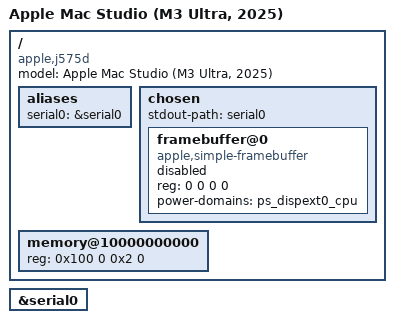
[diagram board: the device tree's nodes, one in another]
// SPDX-License-Identifier: GPL-2.0+ OR MIT
/*
 * Apple Mac Studio (M3 Ultra, 2025)
 *
 * target-type: J575d
 *
 * Copyright The Asahi Linux Contributors
 */

/dts-v1/;

#include "t6032.dtsi"

/ {
	compatible = "apple,j575d", "apple,t6032", "apple,arm-platform";
	model = "Apple Mac Studio (M3 Ultra, 2025)";

	aliases {
		serial0 = &serial0;
	};

	chosen {
		ranges;
		#address-cells = <2>;
		#size-cells = <2>;

		stdout-path = "serial0";

		framebuffer@0 {
			compatible = "apple,simple-framebuffer",
				     "simple-framebuffer";
			reg = <0 0 0 0>; /* To be filled by loader */
			/* Format properties will be added by loader */
			power-domains = <&ps_dispext0_cpu>;

			status = "disabled";
		};
	};

	memory@10000000000 {
		device_type = "memory";
		reg = <0x100 0 0x2 0>; /* To be filled by loader */
	};
};

&serial0 {
	status = "okay";
};
